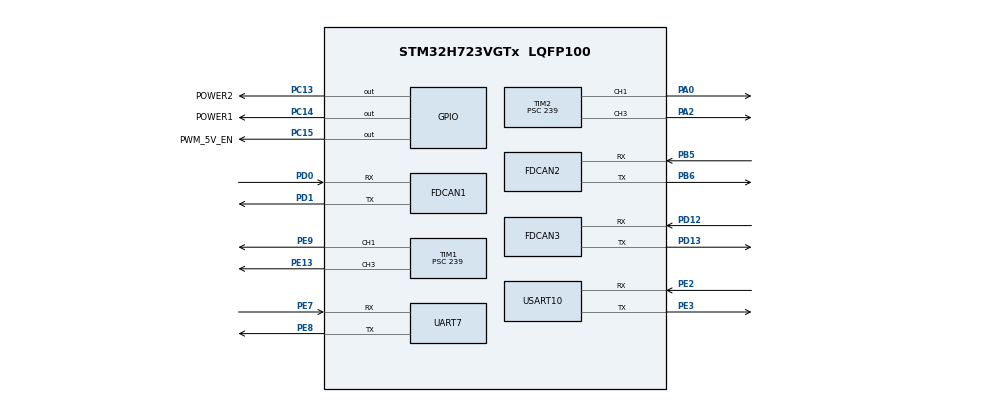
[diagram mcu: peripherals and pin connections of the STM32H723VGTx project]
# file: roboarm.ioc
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CORTEX_M7.default_mode_Activation=1
Dma.Request0=USART10_RX
Dma.Request1=USART10_TX
Dma.USART10_RX.0.Direction=DMA_PERIPH_TO_MEMORY
Dma.USART10_RX.0.EventEnable=DISABLE
Dma.USART10_RX.0.FIFOMode=DMA_FIFOMODE_DISABLE
Dma.USART10_RX.0.Instance=DMA1_Stream0
Dma.USART10_RX.0.MemDataAlignment=DMA_MDATAALIGN_BYTE
Dma.USART10_RX.0.MemInc=DMA_MINC_ENABLE
Dma.USART10_RX.0.Mode=DMA_NORMAL
Dma.USART10_RX.0.PeriphDataAlignment=DMA_PDATAALIGN_BYTE
Dma.USART10_RX.0.PeriphInc=DMA_PINC_DISABLE
Dma.USART10_RX.0.Polarity=HAL_DMAMUX_REQ_GEN_RISING
Dma.USART10_RX.0.Priority=DMA_PRIORITY_LOW
Dma.USART10_RX.0.RequestNumber=1
Dma.USART10_RX.0.SignalID=NONE
Dma.USART10_RX.0.SyncEnable=DISABLE
Dma.USART10_RX.0.SyncPolarity=HAL_DMAMUX_SYNC_NO_EVENT
Dma.USART10_RX.0.SyncRequestNumber=1
Dma.USART10_RX.0.SyncSignalID=NONE
Dma.USART10_TX.1.Direction=DMA_MEMORY_TO_PERIPH
Dma.USART10_TX.1.EventEnable=DISABLE
Dma.USART10_TX.1.FIFOMode=DMA_FIFOMODE_DISABLE
Dma.USART10_TX.1.Instance=DMA1_Stream1
Dma.USART10_TX.1.MemDataAlignment=DMA_MDATAALIGN_BYTE
Dma.USART10_TX.1.MemInc=DMA_MINC_ENABLE
Dma.USART10_TX.1.Mode=DMA_NORMAL
Dma.USART10_TX.1.PeriphDataAlignment=DMA_PDATAALIGN_BYTE
Dma.USART10_TX.1.PeriphInc=DMA_PINC_DISABLE
Dma.USART10_TX.1.Polarity=HAL_DMAMUX_REQ_GEN_RISING
Dma.USART10_TX.1.Priority=DMA_PRIORITY_LOW
Dma.USART10_TX.1.RequestNumber=1
Dma.USART10_TX.1.SignalID=NONE
Dma.USART10_TX.1.SyncEnable=DISABLE
Dma.USART10_TX.1.SyncPolarity=HAL_DMAMUX_SYNC_NO_EVENT
Dma.USART10_TX.1.SyncRequestNumber=1
Dma.USART10_TX.1.SyncSignalID=NONE
FDCAN1.CalculateBaudRateNominal=1000000
FDCAN1.CalculateTimeBitNominal=1000
FDCAN1.CalculateTimeQuantumNominal=25.0
FDCAN1.DataPrescaler=3
FDCAN1.DataSyncJumpWidth=10
FDCAN1.DataTimeSeg1=29
FDCAN1.DataTimeSeg2=10
FDCAN1.MessageRAMOffset=0
FDCAN1.NominalPrescaler=3
FDCAN1.NominalSyncJumpWidth=10
FDCAN1.NominalTimeSeg1=29
FDCAN1.NominalTimeSeg2=10
FDCAN1.RxFifo0ElmtsNbr=4
FDCAN1.StdFiltersNbr=1
FDCAN1.TxFifoQueueElmtsNbr=16
FDCAN2.CalculateBaudRateNominal=1000000
FDCAN2.CalculateTimeBitNominal=1000
FDCAN2.CalculateTimeQuantumNominal=25.0
FDCAN2.DataPrescaler=3
FDCAN2.DataSyncJumpWidth=10
FDCAN2.DataTimeSeg1=29
FDCAN2.DataTimeSeg2=10
FDCAN2.MessageRAMOffset=128
FDCAN2.NominalPrescaler=3
FDCAN2.NominalSyncJumpWidth=10
FDCAN2.NominalTimeSeg1=29
FDCAN2.NominalTimeSeg2=10
FDCAN2.RxFifo0ElmtsNbr=0
FDCAN2.RxFifo1ElmtsNbr=4
FDCAN2.StdFiltersNbr=1
FDCAN2.TxFifoQueueElmtsNbr=16
FDCAN3.CalculateBaudRateNominal=1000000
FDCAN3.CalculateTimeBitNominal=1000
FDCAN3.CalculateTimeQuantumNominal=25.0
FDCAN3.DataPrescaler=3
FDCAN3.DataSyncJumpWidth=10
FDCAN3.DataTimeSeg1=29
FDCAN3.DataTimeSeg2=10
FDCAN3.MessageRAMOffset=256
FDCAN3.NominalPrescaler=3
FDCAN3.NominalSyncJumpWidth=10
FDCAN3.NominalTimeSeg1=29
FDCAN3.NominalTimeSeg2=10
FDCAN3.RxFifo0ElmtsNbr=4
FDCAN3.StdFiltersNbr=1
FDCAN3.TxFifoQueueElmtsNbr=16
FREERTOS.Tasks01=defaultTask,24,128,StartDefaultTask,Default,NULL,Dynamic,NULL,NULL;arm_task,24,512,Arm_Task,As external,NULL,Dynamic,NULL,NULL;arm_calculate_t,24,512,Arm_Calculate_Task,As external,NULL,Dynamic,NULL,NULL;justfloat_task,16,512,Justfloat_Task,As external,NULL,Dynamic,NULL,NULL;pc_comm_task,32,512,PC_Comm_Task,As external,NULL,Dynamic,NULL,NULL
Mcu.Family=STM32H7
Mcu.Name=STM32H723VGTx
Mcu.Package=LQFP100
NVIC.DMA1_Stream0_IRQn=true\:5\:0\:false\:false\:true\:true\:false\:true\:true
NVIC.DMA1_Stream1_IRQn=true\:5\:0\:false\:false\:true\:true\:false\:true\:true
NVIC.FDCAN1_IT0_IRQn=true\:5\:0\:false\:false\:true\:true\:true\:true\:true
NVIC.FDCAN2_IT1_IRQn=true\:5\:0\:false\:false\:true\:true\:true\:true\:true
NVIC.FDCAN3_IT0_IRQn=true\:5\:0\:false\:false\:true\:true\:true\:true\:true
NVIC.PriorityGroup=NVIC_PRIORITYGROUP_4
NVIC.USART10_IRQn=true\:5\:0\:false\:false\:true\:true\:true\:true\:true
PA0.Signal=S_TIM2_CH1_ETR
PA2.Signal=S_TIM2_CH3
PB5.Mode=FDCAN_Activate
PB5.Signal=FDCAN2_RX
PB6.Mode=FDCAN_Activate
PB6.Signal=FDCAN2_TX
PC13.GPIO_Label=POWER2
PC13.GPIO_PuPd=GPIO_PULLUP
PC13.PinState=GPIO_PIN_SET
PC13.Signal=GPIO_Output
PC14-OSC32_IN.GPIO_Label=POWER1
PC14-OSC32_IN.GPIO_PuPd=GPIO_PULLUP
PC14-OSC32_IN.PinState=GPIO_PIN_SET
PC14-OSC32_IN.Signal=GPIO_Output
PC15-OSC32_OUT.GPIO_Label=PWM_5V_EN
PC15-OSC32_OUT.GPIO_PuPd=GPIO_NOPULL
PC15-OSC32_OUT.PinState=GPIO_PIN_RESET
PC15-OSC32_OUT.Signal=GPIO_Output
PD0.Mode=FDCAN_Activate
PD0.Signal=FDCAN1_RX
PD1.Mode=FDCAN_Activate
PD1.Signal=FDCAN1_TX
PD12.Mode=FDCAN_Activate
PD12.Signal=FDCAN3_RX
PD13.Mode=FDCAN_Activate
PD13.Signal=FDCAN3_TX
PE13.Signal=S_TIM1_CH3
PE2.Mode=Asynchronous
PE2.Signal=USART10_RX
PE3.Mode=Asynchronous
PE3.Signal=USART10_TX
PE7.Mode=Asynchronous
PE7.Signal=UART7_RX
PE8.Mode=Asynchronous
PE8.Signal=UART7_TX
PE9.Signal=S_TIM1_CH1
PH0-OSC_IN.Mode=HSE-External-Oscillator
PH0-OSC_IN.Signal=RCC_OSC_IN
PH1-OSC_OUT.Mode=HSE-External-Oscillator
PH1-OSC_OUT.Signal=RCC_OSC_OUT
ProjectManager.HeapSize=0x200
ProjectManager.StackSize=0x400
ProjectManager.TargetToolchain=MDK-ARM V5.32
RCC.ADCFreq_Value=48375000
RCC.APB1Freq_Value=120000000
RCC.APB2Freq_Value=120000000
RCC.APB3Freq_Value=120000000
RCC.APB4Freq_Value=120000000
RCC.CortexFreq_Value=240000000
RCC.D1PPRE=RCC_APB3_DIV2
RCC.D2PPRE1=RCC_APB1_DIV2
RCC.D2PPRE2=RCC_APB2_DIV2
RCC.D3PPRE=RCC_APB4_DIV2
RCC.DIVM1=2
RCC.DIVN1=20
RCC.DIVP1=1
RCC.HCLKFreq_Value=240000000
RCC.HSE_VALUE=24000000
RCC.PLL2FRACN=0
RCC.PLL3FRACN=0
RCC.PLLFRACN=0
RCC.PLLSourceVirtual=RCC_PLLSOURCE_HSE
RCC.SYSCLKFreq_VALUE=240000000
RCC.SYSCLKSource=RCC_SYSCLKSOURCE_PLLCLK
RCC.USBFreq_Value=120000000
SH.S_TIM1_CH1.0=TIM1_CH1,PWM Generation1 CH1
SH.S_TIM1_CH3.0=TIM1_CH3,PWM Generation3 CH3
SH.S_TIM2_CH1_ETR.0=TIM2_CH1,PWM Generation1 CH1
SH.S_TIM2_CH3.0=TIM2_CH3,PWM Generation3 CH3
TIM1.Channel-PWM\ Generation1\ CH1=TIM_CHANNEL_1
TIM1.Channel-PWM\ Generation3\ CH3=TIM_CHANNEL_3
TIM1.Period=19999
TIM1.Prescaler=239
TIM1.Pulse-PWM\ Generation3\ CH3=1500
TIM2.Channel-PWM\ Generation1\ CH1=TIM_CHANNEL_1
TIM2.Channel-PWM\ Generation3\ CH3=TIM_CHANNEL_3
TIM2.Period=19999
TIM2.Prescaler=239
TIM2.Pulse-PWM\ Generation3\ CH3=1500
USART10.VirtualMode=VM_ASYNC
VP_FREERTOS_VS_CMSIS_V2.Mode=CMSIS_V2
VP_MEMORYMAP_VS_MEMORYMAP.Mode=CurAppReg
VP_TIM1_VS_ClockSourceINT.Mode=Internal
VP_TIM2_VS_ClockSourceINT.Mode=Internal
board=custom

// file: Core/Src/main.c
/* USER CODE BEGIN Header */
/**
  ******************************************************************************
  * @file           : main.c
  * @brief          : Main program body
  ******************************************************************************
  * @attention
  *
  * Copyright (c) 2025 STMicroelectronics.
  * All rights reserved.
  *
  * This software is licensed under terms that can be found in the LICENSE file
  * in the root directory of this software component.
  * If no LICENSE file comes with this software, it is provided AS-IS.
  *
  ******************************************************************************
  */
/* USER CODE END Header */
#include "main.h"
#include "FreeRTOS.h"
#include "cmsis_os2.h"
#include "dma.h"
#include "fdcan.h"
#include "tim.h"
#include "usart.h"
#include "gpio.h"

/* USER CODE BEGIN Includes */
/* 应用层模块：达妙电机通信、四路舵机和七轴机械臂控制 */
#include "Motor_baby.h"
#include "Servo.h"
#include "arm_ctrl.h"
#include "PC_comm.h"
/* USER CODE END Includes */

void SystemClock_Config(void);
static void MPU_Config(void);
void MX_FREERTOS_Init(void);

int main(void)
{

  /* MPU Configuration--------------------------------------------------------*/
  MPU_Config();

  /* MCU Configuration--------------------------------------------------------*/

  /* Reset of all peripherals, Initializes the Flash interface and the Systick. */
  HAL_Init();

  /* Configure the system clock */
  SystemClock_Config();

  /* Initialize all configured peripherals */
  MX_GPIO_Init();
  MX_DMA_Init();
  MX_FDCAN1_Init();
  MX_FDCAN2_Init();
  MX_FDCAN3_Init();
  MX_TIM1_Init();
  MX_TIM2_Init();
  MX_UART7_Init();
  MX_USART10_UART_Init();
  /* USER CODE BEGIN 2 */
  /* 初始化三路 FDCAN 的发送帧与接收中断 */
  BSP_FDCAN1_Init();
  BSP_FDCAN2_Init();
  BSP_FDCAN3_Init();
  HAL_Delay(1000);

    /* 初始化舵机，这会停止所有舵机并启动TIM1和TIM2的PWM输出 */
    Servo_Init();

    /* 确保所有舵机处于停止状态 */
    Servo_StopAll();

    /* 拉高 PWM_5V_EN 引脚，为舵机提供5V电源 */
    Servo_EnablePower();

  /* USER CODE END 2 */

  /* Init scheduler */
  osKernelInitialize();  /* Call init function for freertos objects (in cmsis_os2.c) */
  MX_FREERTOS_Init();

  /* Start scheduler */
  osKernelStart();

  /* We should never get here as control is now taken by the scheduler */

  /* Infinite loop */
  /* USER CODE BEGIN WHILE */
  while (1)
  {
//    /* 七轴位置速度控制主循环，内部按 10ms 周期下发 CAN 指令 */
//    Arm_Ctrl_Step();
//    HAL_Delay(10);
    /* USER CODE END WHILE */

  }
}

void SystemClock_Config(void)
{
  RCC_OscInitTypeDef RCC_OscInitStruct = {0};
  RCC_ClkInitTypeDef RCC_ClkInitStruct = {0};

  /** Supply configuration update enable
  */
  HAL_PWREx_ConfigSupply(PWR_LDO_SUPPLY);

  /** Configure the main internal regulator output voltage
  */
  __HAL_PWR_VOLTAGESCALING_CONFIG(PWR_REGULATOR_VOLTAGE_SCALE0);

  while(!__HAL_PWR_GET_FLAG(PWR_FLAG_VOSRDY)) {}

  /** Initializes the RCC Oscillators according to the specified parameters
  * in the RCC_OscInitTypeDef structure.
  */
  RCC_OscInitStruct.OscillatorType = RCC_OSCILLATORTYPE_HSE;
  RCC_OscInitStruct.HSEState = RCC_HSE_ON;
  RCC_OscInitStruct.PLL.PLLState = RCC_PLL_ON;
  RCC_OscInitStruct.PLL.PLLSource = RCC_PLLSOURCE_HSE;
  RCC_OscInitStruct.PLL.PLLM = 2;
  RCC_OscInitStruct.PLL.PLLN = 20;
  RCC_OscInitStruct.PLL.PLLP = 1;
  RCC_OscInitStruct.PLL.PLLQ = 2;
  RCC_OscInitStruct.PLL.PLLR = 2;
  RCC_OscInitStruct.PLL.PLLRGE = RCC_PLL1VCIRANGE_3;
  RCC_OscInitStruct.PLL.PLLVCOSEL = RCC_PLL1VCOWIDE;
  RCC_OscInitStruct.PLL.PLLFRACN = 0;
  if (HAL_RCC_OscConfig(&RCC_OscInitStruct) != HAL_OK)
  {
    Error_Handler();
  }

  /** Initializes the CPU, AHB and APB buses clocks
  */
  RCC_ClkInitStruct.ClockType = RCC_CLOCKTYPE_HCLK|RCC_CLOCKTYPE_SYSCLK
                              |RCC_CLOCKTYPE_PCLK1|RCC_CLOCKTYPE_PCLK2
                              |RCC_CLOCKTYPE_D3PCLK1|RCC_CLOCKTYPE_D1PCLK1;
  RCC_ClkInitStruct.SYSCLKSource = RCC_SYSCLKSOURCE_PLLCLK;
  RCC_ClkInitStruct.SYSCLKDivider = RCC_SYSCLK_DIV1;
  RCC_ClkInitStruct.AHBCLKDivider = RCC_HCLK_DIV1;
  RCC_ClkInitStruct.APB3CLKDivider = RCC_APB3_DIV2;
  RCC_ClkInitStruct.APB1CLKDivider = RCC_APB1_DIV2;
  RCC_ClkInitStruct.APB2CLKDivider = RCC_APB2_DIV2;
  RCC_ClkInitStruct.APB4CLKDivider = RCC_APB4_DIV2;

  if (HAL_RCC_ClockConfig(&RCC_ClkInitStruct, FLASH_LATENCY_3) != HAL_OK)
  {
    Error_Handler();
  }
}

 /* MPU Configuration */

void MPU_Config(void)
{
  MPU_Region_InitTypeDef MPU_InitStruct = {0};

  /* Disables the MPU */
  HAL_MPU_Disable();

  /** Initializes and configures the Region and the memory to be protected
  */
  MPU_InitStruct.Enable = MPU_REGION_ENABLE;
  MPU_InitStruct.Number = MPU_REGION_NUMBER0;
  MPU_InitStruct.BaseAddress = 0x0;
  MPU_InitStruct.Size = MPU_REGION_SIZE_4GB;
  MPU_InitStruct.SubRegionDisable = 0x87;
  MPU_InitStruct.TypeExtField = MPU_TEX_LEVEL0;
  MPU_InitStruct.AccessPermission = MPU_REGION_NO_ACCESS;
  MPU_InitStruct.DisableExec = MPU_INSTRUCTION_ACCESS_DISABLE;
  MPU_InitStruct.IsShareable = MPU_ACCESS_SHAREABLE;
  MPU_InitStruct.IsCacheable = MPU_ACCESS_NOT_CACHEABLE;
  MPU_InitStruct.IsBufferable = MPU_ACCESS_NOT_BUFFERABLE;

  HAL_MPU_ConfigRegion(&MPU_InitStruct);
  /* Enables the MPU */
  HAL_MPU_Enable(MPU_PRIVILEGED_DEFAULT);

}

void Error_Handler(void)
{
  __disable_irq();
  while (1)
  {
  }
}

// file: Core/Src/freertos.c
/* USER CODE BEGIN Header */
/**
  ******************************************************************************
  * File Name          : freertos.c
  * Description        : Code for freertos applications
  ******************************************************************************
  * @attention
  *
  * Copyright (c) 2026 STMicroelectronics.
  * All rights reserved.
  *
  * This software is licensed under terms that can be found in the LICENSE file
  * in the root directory of this software component.
  * If no LICENSE file comes with this software, it is provided AS-IS.
  *
  ******************************************************************************
  */
/* USER CODE END Header */

#include "FreeRTOS.h"
#include "task.h"
#include "main.h"
#include "FreeRTOS.h"
#include "cmsis_os2.h"

/* Definitions for defaultTask */
osThreadId_t defaultTaskHandle;
const osThreadAttr_t defaultTask_attributes = {
  .name = "defaultTask",
  .stack_size = 128 * 4,
  .priority = (osPriority_t) osPriorityNormal,
};
/* Definitions for arm_task */
osThreadId_t arm_taskHandle;
const osThreadAttr_t arm_task_attributes = {
  .name = "arm_task",
  .stack_size = 512 * 4,
  .priority = (osPriority_t) osPriorityNormal,
};
/* Definitions for arm_calculate_t */
osThreadId_t arm_calculate_tHandle;
const osThreadAttr_t arm_calculate_t_attributes = {
  .name = "arm_calculate_t",
  .stack_size = 512 * 4,
  .priority = (osPriority_t) osPriorityNormal,
};
/* Definitions for justfloat_task */
osThreadId_t justfloat_taskHandle;
const osThreadAttr_t justfloat_task_attributes = {
  .name = "justfloat_task",
  .stack_size = 512 * 4,
  .priority = (osPriority_t) osPriorityBelowNormal,
};
/* Definitions for pc_comm_task */
osThreadId_t pc_comm_taskHandle;
const osThreadAttr_t pc_comm_task_attributes = {
  .name = "pc_comm_task",
  .stack_size = 512 * 4,
  .priority = (osPriority_t) osPriorityAboveNormal,
};

void StartDefaultTask(void *argument);
extern void Arm_Task(void *argument);
extern void Arm_Calculate_Task(void *argument);
extern void Justfloat_Task(void *argument);
extern void PC_Comm_Task(void *argument);

void MX_FREERTOS_Init(void); /* (MISRA C 2004 rule 8.1) */

void MX_FREERTOS_Init(void) {

  /* Create the thread(s) */
  /* creation of defaultTask */
  defaultTaskHandle = osThreadNew(StartDefaultTask, NULL, &defaultTask_attributes);

  /* creation of arm_task */
  arm_taskHandle = osThreadNew(Arm_Task, NULL, &arm_task_attributes);

  /* creation of arm_calculate_t */
  arm_calculate_tHandle = osThreadNew(Arm_Calculate_Task, NULL, &arm_calculate_t_attributes);

  /* creation of justfloat_task */
  justfloat_taskHandle = osThreadNew(Justfloat_Task, NULL, &justfloat_task_attributes);

  /* creation of pc_comm_task */
  pc_comm_taskHandle = osThreadNew(PC_Comm_Task, NULL, &pc_comm_task_attributes);

}

void StartDefaultTask(void *argument)
{
  for(;;)
  {
    osDelay(1);
  }
}
